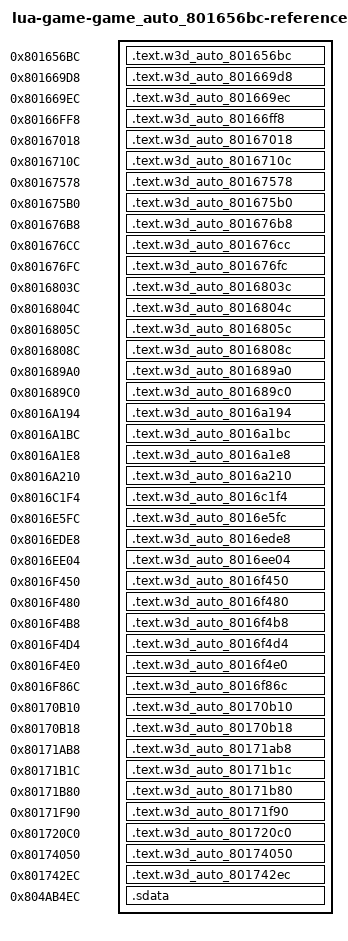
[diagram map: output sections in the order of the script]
/* Generated reference-only placements. All bodies are source-built. */
OUTPUT_FORMAT("elf32-powerpc")
OUTPUT_ARCH(powerpc)
ENTRY(w3d_auto_801656bc)
_SDA_BASE_ = 0x804b2540;
_SDA2_BASE_ = 0x804c2540;
fn_8016703C = 0x8016703c;
fn_8016804C = 0x8016804c;
fn_801686A0 = 0x801686a0;
fn_8016EE44 = 0x8016ee44;
fn_801720FC = 0x801720fc;
fn_80174074 = 0x80174074;
fn_801A314C = 0x801a314c;
fn_801A3164 = 0x801a3164;
fn_801A38C8 = 0x801a38c8;
fn_801D4544 = 0x801d4544;
fn_80209968 = 0x80209968;
fn_8030AF88 = 0x8030af88;
fn_8030BA64 = 0x8030ba64;
fn_8030BFF4 = 0x8030bff4;
fn_8030C044 = 0x8030c044;
fn_8030C094 = 0x8030c094;
fn_8034BF48 = 0x8034bf48;
SECTIONS {
  .text.w3d_auto_801656bc 0x801656bc : { *(.text.w3d_auto_801656bc) }
  .text.w3d_auto_801669d8 0x801669d8 : { *(.text.w3d_auto_801669d8) }
  .text.w3d_auto_801669ec 0x801669ec : { *(.text.w3d_auto_801669ec) }
  .text.w3d_auto_80166ff8 0x80166ff8 : { *(.text.w3d_auto_80166ff8) }
  .text.w3d_auto_80167018 0x80167018 : { *(.text.w3d_auto_80167018) }
  .text.w3d_auto_8016710c 0x8016710c : { *(.text.w3d_auto_8016710c) }
  .text.w3d_auto_80167578 0x80167578 : { *(.text.w3d_auto_80167578) }
  .text.w3d_auto_801675b0 0x801675b0 : { *(.text.w3d_auto_801675b0) }
  .text.w3d_auto_801676b8 0x801676b8 : { *(.text.w3d_auto_801676b8) }
  .text.w3d_auto_801676cc 0x801676cc : { *(.text.w3d_auto_801676cc) }
  .text.w3d_auto_801676fc 0x801676fc : { *(.text.w3d_auto_801676fc) }
  .text.w3d_auto_8016803c 0x8016803c : { *(.text.w3d_auto_8016803c) }
  .text.w3d_auto_8016804c 0x8016804c : { *(.text.w3d_auto_8016804c) }
  .text.w3d_auto_8016805c 0x8016805c : { *(.text.w3d_auto_8016805c) }
  .text.w3d_auto_8016808c 0x8016808c : { *(.text.w3d_auto_8016808c) }
  .text.w3d_auto_801689a0 0x801689a0 : { *(.text.w3d_auto_801689a0) }
  .text.w3d_auto_801689c0 0x801689c0 : { *(.text.w3d_auto_801689c0) }
  .text.w3d_auto_8016a194 0x8016a194 : { *(.text.w3d_auto_8016a194) }
  .text.w3d_auto_8016a1bc 0x8016a1bc : { *(.text.w3d_auto_8016a1bc) }
  .text.w3d_auto_8016a1e8 0x8016a1e8 : { *(.text.w3d_auto_8016a1e8) }
  .text.w3d_auto_8016a210 0x8016a210 : { *(.text.w3d_auto_8016a210) }
  .text.w3d_auto_8016c1f4 0x8016c1f4 : { *(.text.w3d_auto_8016c1f4) }
  .text.w3d_auto_8016e5fc 0x8016e5fc : { *(.text.w3d_auto_8016e5fc) }
  .text.w3d_auto_8016ede8 0x8016ede8 : { *(.text.w3d_auto_8016ede8) }
  .text.w3d_auto_8016ee04 0x8016ee04 : { *(.text.w3d_auto_8016ee04) }
  .text.w3d_auto_8016f450 0x8016f450 : { *(.text.w3d_auto_8016f450) }
  .text.w3d_auto_8016f480 0x8016f480 : { *(.text.w3d_auto_8016f480) }
  .text.w3d_auto_8016f4b8 0x8016f4b8 : { *(.text.w3d_auto_8016f4b8) }
  .text.w3d_auto_8016f4d4 0x8016f4d4 : { *(.text.w3d_auto_8016f4d4) }
  .text.w3d_auto_8016f4e0 0x8016f4e0 : { *(.text.w3d_auto_8016f4e0) }
  .text.w3d_auto_8016f86c 0x8016f86c : { *(.text.w3d_auto_8016f86c) }
  .text.w3d_auto_80170b10 0x80170b10 : { *(.text.w3d_auto_80170b10) }
  .text.w3d_auto_80170b18 0x80170b18 : { *(.text.w3d_auto_80170b18) }
  .text.w3d_auto_80171ab8 0x80171ab8 : { *(.text.w3d_auto_80171ab8) }
  .text.w3d_auto_80171b1c 0x80171b1c : { *(.text.w3d_auto_80171b1c) }
  .text.w3d_auto_80171b80 0x80171b80 : { *(.text.w3d_auto_80171b80) }
  .text.w3d_auto_80171f90 0x80171f90 : { *(.text.w3d_auto_80171f90) }
  .text.w3d_auto_801720c0 0x801720c0 : { *(.text.w3d_auto_801720c0) }
  .text.w3d_auto_80174050 0x80174050 : { *(.text.w3d_auto_80174050) }
  .text.w3d_auto_801742ec 0x801742ec : { *(.text.w3d_auto_801742ec) }
  .sdata 0x804ab4ec (NOLOAD) : {
    . = 0x0; lbl_804AB4EC = .;
    . = 0x4bf0; lbl_804B00DC = .;
    . = 0x4c38; lbl_804B0124 = .;
    . = 0x4c3c; lbl_804B0128 = .;
    . = 0x4c48; lbl_804B0134 = .;
    . = 0x4c4c; lbl_804B0138 = .;
    . = 0x4c54; lbl_804B0140 = .;
    . = 0x4c58; lbl_804B0144 = .;
    . = 0x6398; lbl_804B1884 = .;
    . = 0x63b8; lbl_804B18A4 = .;
    . = 0x63ba; lbl_804B18A6 = .;
    . += 1; }
  /DISCARD/ : { *(.text*) *(.rodata*) *(.data*) *(.bss*) *(.sdata*) *(.sbss*) *(.comment) }
}
